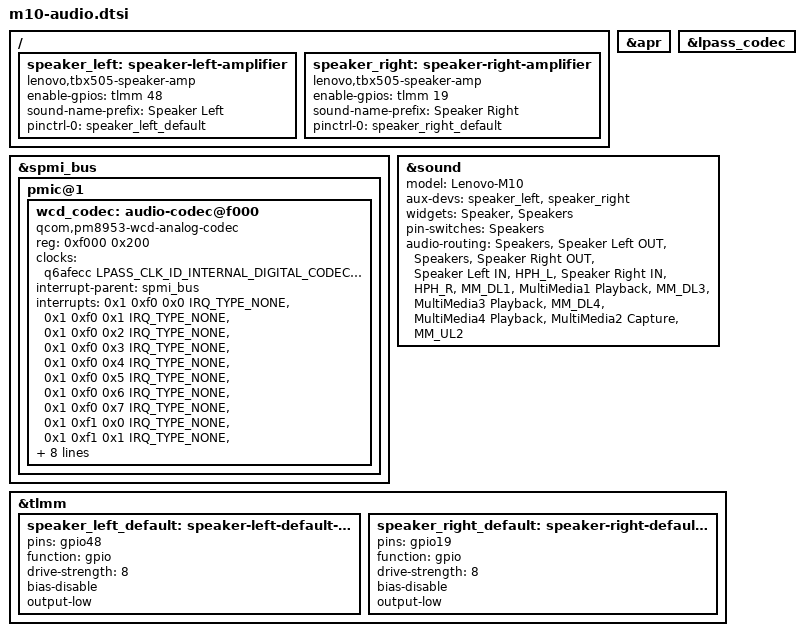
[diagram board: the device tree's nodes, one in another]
// SPDX-License-Identifier: BSD-3-Clause
&spmi_bus {
 pmic@1 {
		wcd_codec: audio-codec@f000 {
			compatible = "qcom,pm8953-wcd-analog-codec";
			reg = <0xf000 0x200>;
			reg-names = "pmic-codec-core";
			clocks = <&q6afecc LPASS_CLK_ID_INTERNAL_DIGITAL_CODEC_CORE
					   LPASS_CLK_ATTRIBUTE_COUPLE_NO>;
			clock-names = "mclk";
			interrupt-parent = <&spmi_bus>;
			interrupts = <0x1 0xf0 0x0 IRQ_TYPE_NONE>,
				     <0x1 0xf0 0x1 IRQ_TYPE_NONE>,
				     <0x1 0xf0 0x2 IRQ_TYPE_NONE>,
				     <0x1 0xf0 0x3 IRQ_TYPE_NONE>,
				     <0x1 0xf0 0x4 IRQ_TYPE_NONE>,
				     <0x1 0xf0 0x5 IRQ_TYPE_NONE>,
				     <0x1 0xf0 0x6 IRQ_TYPE_NONE>,
				     <0x1 0xf0 0x7 IRQ_TYPE_NONE>,
				     <0x1 0xf1 0x0 IRQ_TYPE_NONE>,
				     <0x1 0xf1 0x1 IRQ_TYPE_NONE>,
				     <0x1 0xf1 0x2 IRQ_TYPE_NONE>,
				     <0x1 0xf1 0x3 IRQ_TYPE_NONE>,
				     <0x1 0xf1 0x4 IRQ_TYPE_NONE>,
				     <0x1 0xf1 0x5 IRQ_TYPE_NONE>;
			interrupt-names = "cdc_spk_cnp_int",
					  "cdc_spk_clip_int",
					  "cdc_spk_ocp_int",
					  "mbhc_ins_rem_det1",
					  "mbhc_but_rel_det",
					  "mbhc_but_press_det",
					  "mbhc_ins_rem_det",
					  "mbhc_switch_int",
					  "cdc_ear_ocp_int",
					  "cdc_hphr_ocp_int",
					  "cdc_hphl_ocp_det",
					  "cdc_ear_cnp_int",
					  "cdc_hphr_cnp_int",
					  "cdc_hphl_cnp_int";

			#sound-dai-cells = <1>;

			vdd-cdc-io-supply = <&pm8953_l5>;
            vdd-cdc-tx-rx-cx-supply = <&pm8953_s4>;
            vdd-micbias-supply = <&pm8953_l13>;
            qcom,micbias2-ext-cap;
            status = "okay";
		};
 };
};
#include "msm8937-qdsp6.dtsi"

/ {
    speaker_left: speaker-left-amplifier {
        compatible = "lenovo,tbx505-speaker-amp";
        enable-gpios = <&tlmm 48 GPIO_ACTIVE_HIGH>;
        sound-name-prefix = "Speaker Left";
        pinctrl-names = "default";
        pinctrl-0 = <&speaker_left_default>;
    };
    speaker_right: speaker-right-amplifier {
        compatible = "lenovo,tbx505-speaker-amp";
        enable-gpios = <&tlmm 19 GPIO_ACTIVE_HIGH>;
        sound-name-prefix = "Speaker Right";
        pinctrl-names = "default";
        pinctrl-0 = <&speaker_right_default>;
    };
};
&apr { status = "okay"; };
&lpass_codec { status = "okay"; };
&sound {
    model = "Lenovo-M10";
    aux-devs = <&speaker_left>, <&speaker_right>;
    widgets = "Speaker", "Speakers";
    pin-switches = "Speakers";
    audio-routing =
        "Speakers", "Speaker Left OUT",
        "Speakers", "Speaker Right OUT",
        "Speaker Left IN", "HPH_L",
        "Speaker Right IN", "HPH_R",
        "MM_DL1", "MultiMedia1 Playback",
        "MM_DL3", "MultiMedia3 Playback",
        "MM_DL4", "MultiMedia4 Playback",
        "MultiMedia2 Capture", "MM_UL2";
    status = "okay";
};

&tlmm {
    speaker_left_default: speaker-left-default-state {
        pins = "gpio48";
        function = "gpio";
        drive-strength = <8>;
        bias-disable;
        output-low;
    };
    speaker_right_default: speaker-right-default-state {
        pins = "gpio19";
        function = "gpio";
        drive-strength = <8>;
        bias-disable;
        output-low;
    };
};
